# STM32F407Test register map
File version: 1.0
Test device with 50 peripherals
CPU: CM0+ r0p1, little endian, MPU, no FPU, 4 interrupt priority bits
Registers are 32-bit, read-write, reset 0x0 unless marked. A register's access mark holds for its fields unless they carry their own. Offsets are from the block's base; lines under a group give offsets from that group; [hi:lo] are bit positions; {n}, {i} and the like mark numbered series; 'fields as' and 'values as' point back to an identical list; <NAME> marks a mode.

## Memory map
0x40000000 TIM2 size 0x14 — General-purpose timer 2
0x40000400 TIM3 size 0x14 — General-purpose timer 3
0x40000800 TIM4 size 0x14 — General-purpose timer 4
0x40000C00 TIM5 size 0x14 — General-purpose timer 5
0x40002800 RTC size 0x14 — Real-time clock
0x40002C00 WWDG size 0x14 — Window watchdog
0x40003000 IWDG size 0x14 — Independent watchdog
0x40003800 SPI2 size 0x14
0x40003C00 SPI3 size 0x14
0x40004400 USART2 size 0x14 — USART 1
0x40004800 USART3 size 0x14 — USART 1
0x40004C00 UART4 size 0x14 — USART 1
0x40005000 UART5 size 0x14 — USART 1
0x40005400 I2C1 size 0x14
0x40005800 I2C2 size 0x14
0x40005C00 I2C3 size 0x14
0x40006400 CAN1 size 0x14
0x40006800 CAN2 size 0x14
0x40007000 PWR size 0x14 — Power controller
0x40007400 DAC size 0x14 — Digital-to-analog converter
0x40010000 TIM1 size 0x14 — Advanced-control timer 1
0x40011000 USART1 size 0x14
0x40011400 USART6 size 0x14 — USART 1
0x40012000 ADC1 size 0x14
0x40012100 ADC2 size 0x14
0x40012200 ADC3 size 0x14
0x40013000 SPI1 size 0x14
0x40013800 SYSCFG size 0x14 — System configuration controller
0x40013C00 EXTI size 0x14 — External interrupt/event controller
0x40014000 TIM9 size 0x14 — General-purpose timer 9
0x40014400 TIM10 size 0x14 — General-purpose timer 10
0x40014800 TIM11 size 0x14 — General-purpose timer 11
0x40023000 CRC size 0x14 — CRC calculation unit
0x40023800 RCC size 0x14 — Reset and clock control
0x40023C00 FLASH size 0x14 — Flash memory interface
0x40026000 DMA1 size 0x14 — DMA controller 1
0x40026400 DMA2 size 0x14 — DMA controller 2
0x40028000 ETHERNET_MAC size 0x14
0x48010000 GPIOA size 0x14 — General-purpose I/O port A
0x50000000 OTG_FS size 0x14 — USB OTG full speed
0x50060800 RNG size 0x14 — Random number generator
0xE000E100 NVIC size 0x14 — Nested vectored interrupt controller
0xE000ED00 SCB size 0x14 — System control block
0xE0042000 DBGMCU size 0x14 — Debug MCU
0x400200400 GPIOB size 0x14 — General-purpose I/O port B
0x400200800 GPIOC size 0x14 — General-purpose I/O port C
0x400200C00 GPIOD size 0x14 — General-purpose I/O port D
0x400201000 GPIOE size 0x14 — General-purpose I/O port E
0x400201400 GPIOF size 0x14 — General-purpose I/O port F
0x400201800 GPIOG size 0x14 — General-purpose I/O port G
0x400201C00 GPIOH size 0x14 — General-purpose I/O port H
0x400202000 GPIOI size 0x14 — General-purpose I/O port I

## GPIOA — General-purpose I/O port A
Base 0x48010000
Same registers: GPIOB 0x400200400, GPIOC 0x400200800, GPIOD 0x400200C00, GPIOE 0x400201000, GPIOF 0x400201400, GPIOG 0x400201800, GPIOH 0x400201C00, GPIOI 0x400202000
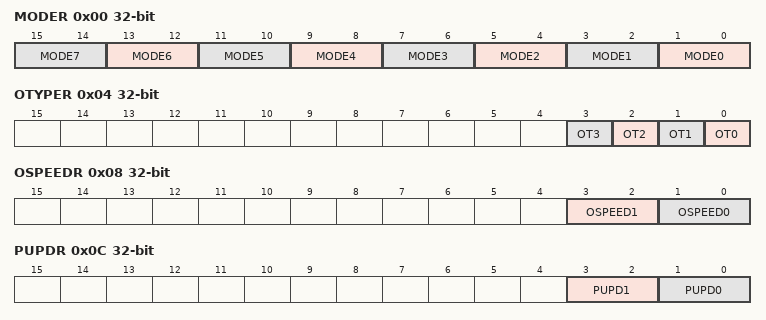
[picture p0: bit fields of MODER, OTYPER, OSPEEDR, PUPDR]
0x00 MODER — Port mode register
  [2n+1:2n] MODE{n} (n=0..7)
0x04 OTYPER — Port output type register
  [n] OT{n} (n=0..3)
0x08 OSPEEDR — Port output speed register
  [3:2] OSPEED1, [1:0] OSPEED0
0x0C PUPDR — Port pull-up/pull-down register
  [3:2] PUPD1, [1:0] PUPD0
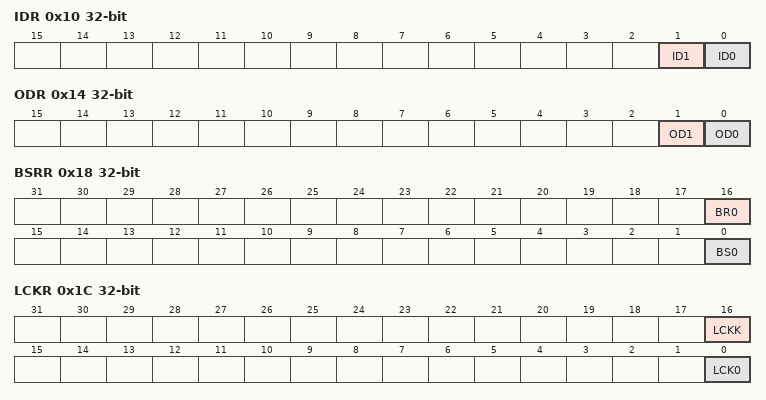
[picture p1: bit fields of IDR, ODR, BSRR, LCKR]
0x10 IDR — Port input data register
  [1] ID1, [0] ID0
0x14 ODR — Port output data register
  [1] OD1, [0] OD0
0x18 BSRR — Port bit set/reset register
  [16] BR0, [0] BS0
0x1C LCKR — Port configuration lock register
  [16] LCKK, [0] LCK0
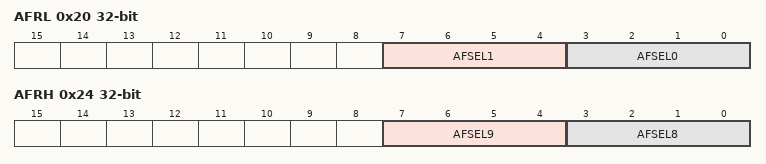
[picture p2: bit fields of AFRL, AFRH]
0x20 AFRL — Alternate function low register
  [7:4] AFSEL1, [3:0] AFSEL0
0x24 AFRH — Alternate function high register
  [7:4] AFSEL9, [3:0] AFSEL8

## DMA1 — DMA controller 1
Base 0x40026000
Same registers: DMA2 0x40026400
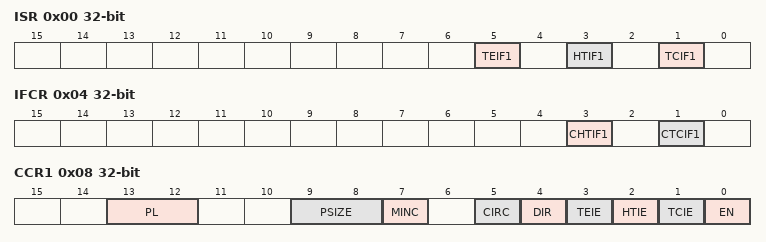
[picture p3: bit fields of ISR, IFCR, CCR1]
0x00 ISR — DMA interrupt status register
  [5] TEIF1, [3] HTIF1, [1] TCIF1
0x04 IFCR — DMA interrupt flag clear register
  [3] CHTIF1, [1] CTCIF1
0x08 CCR1 — DMA channel 1 configuration
  [13:12] PL, [9:8] PSIZE, [7] MINC, [5] CIRC, [4] DIR, [3] TEIE, [2] HTIE, [1] TCIE, [0] EN
0x0C CNDTR1 — DMA channel 1 number of data
  [15:0] NDT
0x10 CPAR1 — DMA channel 1 peripheral address
  [31:0] PA
0x14 CMAR1 — DMA channel 1 memory address
  [31:0] MA
